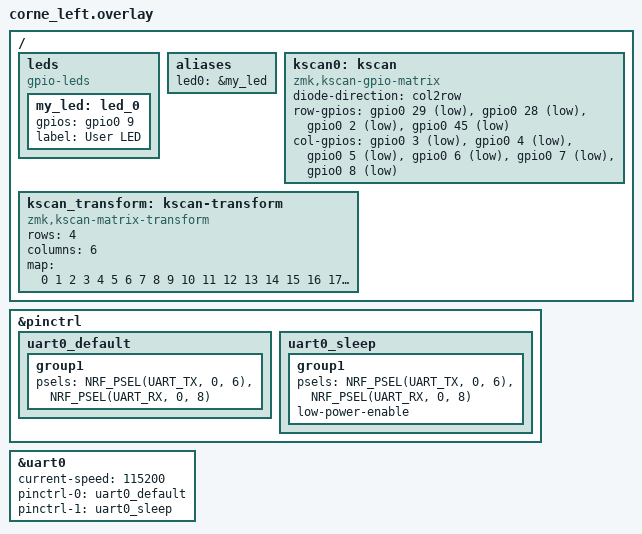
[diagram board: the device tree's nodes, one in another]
&pinctrl {
    uart0_default: uart0_default {
        group1 {
            psels = <NRF_PSEL(UART_TX, 0, 6)>,
                    <NRF_PSEL(UART_RX, 0, 8)>;
        };
    };

    uart0_sleep: uart0_sleep {
        group1 {
            psels = <NRF_PSEL(UART_TX, 0, 6)>,
                    <NRF_PSEL(UART_RX, 0, 8)>;
            low-power-enable;
        };
    };
};

&uart0 {
    status = "okay";
    current-speed = <115200>;
    pinctrl-0 = <&uart0_default>;
    pinctrl-1 = <&uart0_sleep>;
    pinctrl-names = "default", "sleep";
};

/ {
    leds {
        compatible = "gpio-leds";
        my_led: led_0 {
            gpios = <&gpio0 9 GPIO_ACTIVE_HIGH>;
            label = "User LED";
        };
    };

    aliases {
        led0 = &my_led;
    };

    // Adicione isso para o mapeamento do lado esquerdo
    kscan0: kscan {
        compatible = "zmk,kscan-gpio-matrix";
        diode-direction = "col2row";

        // Troque os pinos abaixo pelos seus rows/cols reais do lado esquerdo
        row-gpios = <&gpio0 29 (GPIO_ACTIVE_LOW | GPIO_PULL_UP)>,
                    <&gpio0 28 (GPIO_ACTIVE_LOW | GPIO_PULL_UP)>,
                    <&gpio0 2  (GPIO_ACTIVE_LOW | GPIO_PULL_UP)>,
                    <&gpio0 45 (GPIO_ACTIVE_LOW | GPIO_PULL_UP)>;

        col-gpios = <&gpio0 3  (GPIO_ACTIVE_LOW | GPIO_PULL_UP)>,
                    <&gpio0 4  (GPIO_ACTIVE_LOW | GPIO_PULL_UP)>,
                    <&gpio0 5  (GPIO_ACTIVE_LOW | GPIO_PULL_UP)>,
                    <&gpio0 6  (GPIO_ACTIVE_LOW | GPIO_PULL_UP)>,
                    <&gpio0 7  (GPIO_ACTIVE_LOW | GPIO_PULL_UP)>,
                    <&gpio0 8  (GPIO_ACTIVE_LOW | GPIO_PULL_UP)>;
    };

    kscan_transform: kscan-transform {
        compatible = "zmk,kscan-matrix-transform";
        rows = <4>;
        columns = <6>;

        // Lado esquerdo ocupa índices 0..23
        map = <
            0  1  2  3  4  5
            6  7  8  9  10 11
            12 13 14 15 16 17
            18 19 20 21 22 23
        >;
    };
};

/* &central_behavior {
    compatible = "zmk,behavior-split-central";
}; */

/* & {
    chosen {
        zmk,run-behavior = &central_behavior;
    };
}; */
